# BL808 register map
File version: 0.1
Registers are access not given, no defined reset value unless marked. A register's access mark holds for its fields unless they carry their own. Offsets are from the block's base; [hi:lo] are bit positions; {n}, {i} and the like mark numbered series.

## TIMER1
Base 0x30009000
Same registers: TIMER0 0x2000A500
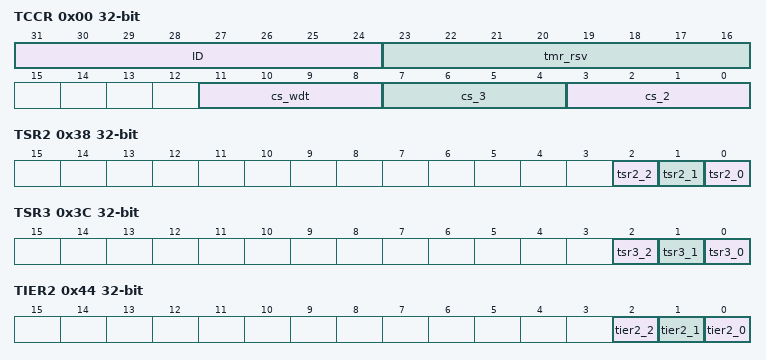
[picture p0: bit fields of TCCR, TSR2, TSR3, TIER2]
0x00 TCCR
  [31:24] ID ro
  [23:16] tmr_rsv
  [11:8] cs_wdt rw — WDT 0:fclk / 1:f32k / 2:1k / 3:32M / 4:GPIO / 5:No clock
  [7:4] cs_3 rw — Timer3 0:fclk / 1:f32k / 2:1k / 3:32M / 4:GPIO / 5:No clock
  [3:0] cs_2 rw — Timer2 0:fclk / 1:f32k / 2:1k / 3:32M / 4:GPIO / 5:No clock
{0x10+4i} TMR2_{i} rw (i=0..2)
  [31:0] tmr2_{i} — Timer2 Match Value {i}
{0x1C+4i} TMR3_{i} rw (i=0..2)
  [31:0] tmr3_{i} — Timer3 Match Value {i}
0x2C TCR2 ro
  [31:0] tcr2_cnt — Timer2 Counter Value
0x30 TCR3 ro
  [31:0] tcr3_cnt — Timer3 Counter Value
0x38 TSR2
  [2] tsr2_2 ro — Timer2 match value 2 status/Clear interrupt would also clear this bit
  [1] tsr2_1 ro — Timer2 match value 1 status/Clear interrupt would also clear this bit
  [0] tsr2_0 ro — Timer2 match value 0 status/Clear interrupt would also clear this bit
0x3C TSR3
  [2] tsr3_2 ro — Timer3 match value 2 status/Clear interrupt would also clear this bit
  [1] tsr3_1 ro — Timer3 match value 1 status/Clear interrupt would also clear this bit
  [0] tsr3_0 ro — Timer3 match value 0 status/Clear interrupt would also clear this bit
0x44 TIER2
  [2] tier2_2 rw — Timer2 match value 2 interrupt enable
  [1] tier2_1 rw — Timer2 match value 1 interrupt enable
  [0] tier2_0 rw — Timer2 match value 0 interrupt enable
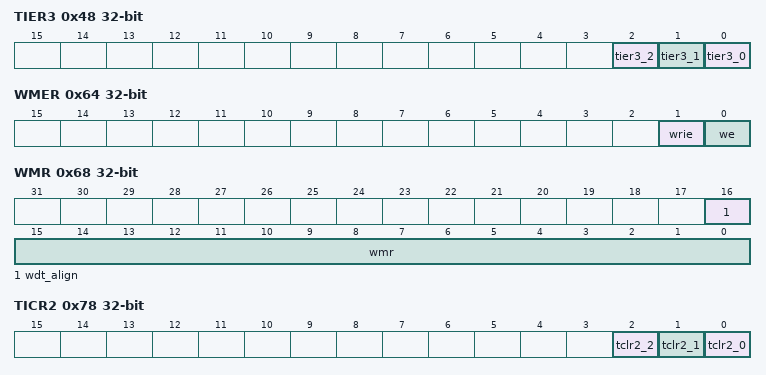
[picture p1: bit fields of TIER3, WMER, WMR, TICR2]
0x48 TIER3
  [2] tier3_2 rw — Timer3 match value 2 interrupt enable
  [1] tier3_1 rw — Timer3 match value 1 interrupt enable
  [0] tier3_0 rw — Timer3 match value 0 interrupt enable
0x50 TPLVR2 rw
  [31:0] tplvr2 — Timer2 Pre-Load Value
0x54 TPLVR3 rw
  [31:0] tplvr3 — Timer3 Pre-Load Value
0x5C TPLCR2
  [1:0] tplcr2 rw — Timer2 pre-load control 2'd0 - No pre-load 2'd1 - Pre-load with match comparator 0 2'd2 - Pre-load with match comparator 1 2'd3 - Pre-load with match comparator 2
0x60 TPLCR3
  [1:0] tplcr3 rw — Timer3 pre-load control 2'd0 - No pre-load 2'd1 - Pre-load with match comparator 0 2'd2 - Pre-load with match comparator 1 2'd3 - Pre-load with match comparator 2
0x64 WMER
  [1] wrie rw — WDT reset/interrupt mode 1'b0 - WDT expiration to generate interrupt 1'b1 - WDT expiration to generate reset source
  [0] we rw — WDT enable register
0x68 WMR
  [16] wdt_align rw — WDT compare value update align interrupt
  [15:0] wmr rw — WDT counter match value
0x6C WVR
  [15:0] wdt_cnt ro — WDT counter value
0x70 WSR
  [0] wts wo — WDT reset status Write 0 to clear the WDT reset status Read 1 indicates reset was caused by the WDT
0x78 TICR2
  [2] tclr2_2 wo — Timer2 Interrupt clear for match comparator 2
  [1] tclr2_1 wo — Timer2 Interrupt clear for match comparator 1
  [0] tclr2_0 wo — Timer2 Interrupt clear for match comparator 0
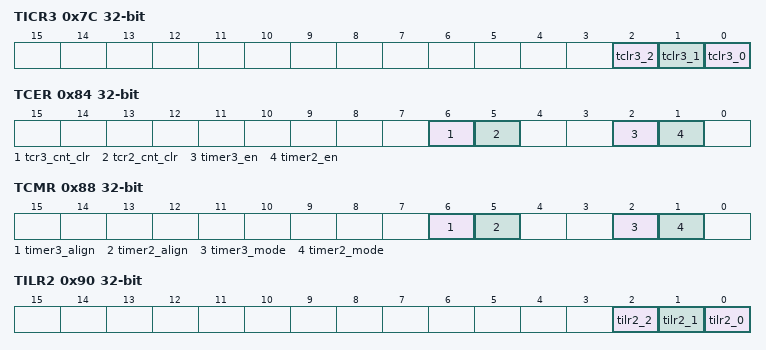
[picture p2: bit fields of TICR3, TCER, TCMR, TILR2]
0x7C TICR3
  [2] tclr3_2 wo — Timer3 Interrupt clear for match comparator 2
  [1] tclr3_1 wo — Timer3 Interrupt clear for match comparator 1
  [0] tclr3_0 wo — Timer3 Interrupt clear for match comparator 0
0x80 WICR
  [0] wiclr wo — WDT Interrupt Clear
0x84 TCER
  [6] tcr3_cnt_clr rw — Timer3 count clear
  [5] tcr2_cnt_clr rw — Timer2 count clear
  [2] timer3_en rw — Timer3 count enable
  [1] timer2_en rw — Timer2 count enable
0x88 TCMR
  [6] timer3_align rw — Timer3 compare value update align interrupt
  [5] timer2_align rw — Timer2 compare value update align interrupt
  [2] timer3_mode rw — 0:pre-load mode 1:free run mode
  [1] timer2_mode rw — 0:pre-load mode 1:free run mode
0x90 TILR2
  [2] tilr2_2 rw — 0:level 1:edge
  [1] tilr2_1 rw — 0:level 1:edge
  [0] tilr2_0 rw — 0:level 1:edge
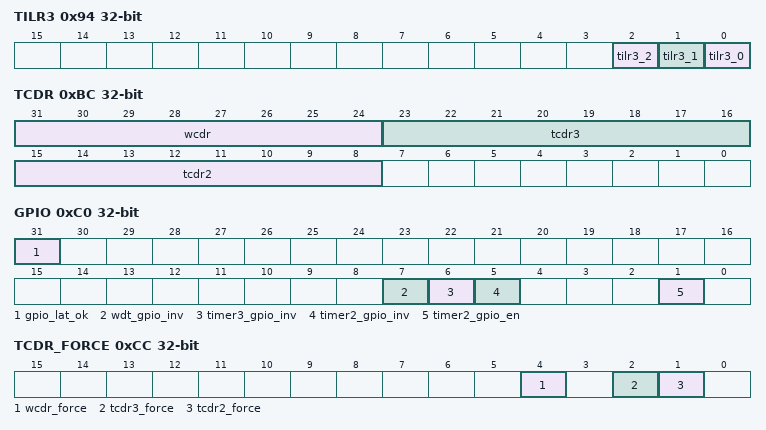
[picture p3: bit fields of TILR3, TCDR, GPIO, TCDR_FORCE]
0x94 TILR3
  [2] tilr3_2 rw — 0:level 1:edge
  [1] tilr3_1 rw — 0:level 1:edge
  [0] tilr3_0 rw — 0:level 1:edge
0x98 WCR
  [0] wcr wo — WDT Counter Reset
0x9C WFAR
  [15:0] wfar wo — WDT access key1 - 16'hBABA
0xA0 WSAR
  [15:0] wsar wo — WDT access key2 - 16'hEB10
0xA8 TCVWR2 ro
  [31:0] tcr2_cnt_lat — Timer2 Counter Latch Value
0xAC TCVWR3 ro
  [31:0] tcr3_cnt_lat — Timer3 Counter Latch Value
0xB4 TCVSYN2 ro
  [31:0] tcr2_cnt_sync — Timer2 Counter Sync Value (continue readable)
0xB8 TCVSYN3 ro
  [31:0] tcr3_cnt_sync — Timer3 Counter Sync Value (continue readable)
0xBC TCDR
  [31:24] wcdr rw — WDT clock division value register
  [23:16] tcdr3 rw — Timer3 clock division value register
  [15:8] tcdr2 rw — Timer2 clock division value register
0xC0 GPIO
  [31] gpio_lat_ok ro — Latch Done. Pulse width = (GPIO_LAT2 - GPIO_LAT1) * (Timer2 Cycle)
  [7] wdt_gpio_inv rw — WDT gpio polarity 0:pos 1:neg
  [6] timer3_gpio_inv rw — Timer3 gpio polarity 0:pos 1:neg
  [5] timer2_gpio_inv rw — Timer2 gpio polarity 0:pos 1:neg
  [1] timer2_gpio_en rw — Timer2 gpio measure enable
0xC4 GPIO_LAT1 ro
  [31:0] gpio_lat1 — Pos-Edge Latch Timer2
0xC8 GPIO_LAT2 ro
  [31:0] gpio_lat2 — Neg-Edge Latch Timer2
0xCC TCDR_FORCE
  [4] wcdr_force rw — Force WDT clock division value to counter
  [2] tcdr3_force rw — Force Timer3 clock division value to counter
  [1] tcdr2_force rw — Force Timer2 clock division value to counter
